# ESP32-S31 register map
Vendor: ESPRESSIF SYSTEMS (SHANGHAI) CO., LTD.; Series: ESP32 S-Series; File version: 1
CPU: RV32IMAFC r0p0, little endian, no MPU, FPU, 0 interrupt priority bits
Address unit: 32 bits
Registers are 32-bit, read-write, reset 0x0 unless marked. A register's access mark holds for its fields unless they carry their own. Offsets are from the block's base; [hi:lo] are bit positions; {n}, {i} and the like mark numbered series; 'fields as' and 'values as' point back to an identical list.

## IOMUX_MSPI_PIN — IOMUX_MSPI_PIN Peripheral
Base 0x20584000
0x00 CLK_EN0 reset 0x1 — apb registers auto clock gating reg
  [0] REG_CLK_EN — 1: auto clock gating on 0: auto clock gating off
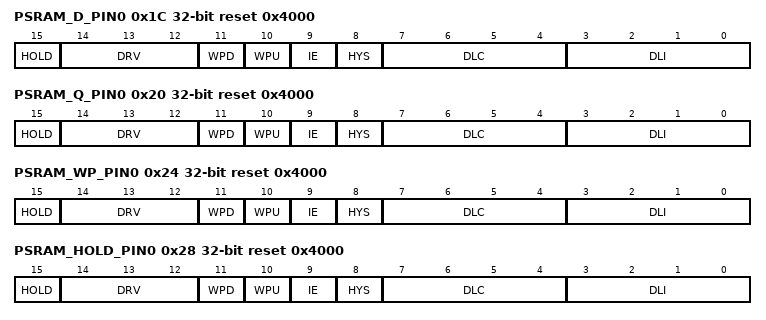
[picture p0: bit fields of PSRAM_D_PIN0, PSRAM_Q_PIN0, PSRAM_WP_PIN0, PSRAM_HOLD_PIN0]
0x1C PSRAM_D_PIN0 reset 0x4000 — IOMUX_MSPI_PIN_PSRAM_D_PIN0_REG
  [15] HOLD — psram d hold
  [14:12] DRV — psram d drv
  [11] WPD — psram d wpd
  [10] WPU — psram d wpu
  [9] IE — Reserved
  [8] HYS — psram d sl
  [7:4] DLC — psram d dlc
  [3:0] DLI — psram d dli
0x20 PSRAM_Q_PIN0 reset 0x4000 — IOMUX_MSPI_PIN_PSRAM_D_PIN0_REG
  fields as PSRAM_D_PIN0
0x24 PSRAM_WP_PIN0 reset 0x4000 — IOMUX_MSPI_PIN_PSRAM_D_PIN0_REG
  fields as PSRAM_D_PIN0
0x28 PSRAM_HOLD_PIN0 reset 0x4000 — IOMUX_MSPI_PIN_PSRAM_D_PIN0_REG
  fields as PSRAM_D_PIN0
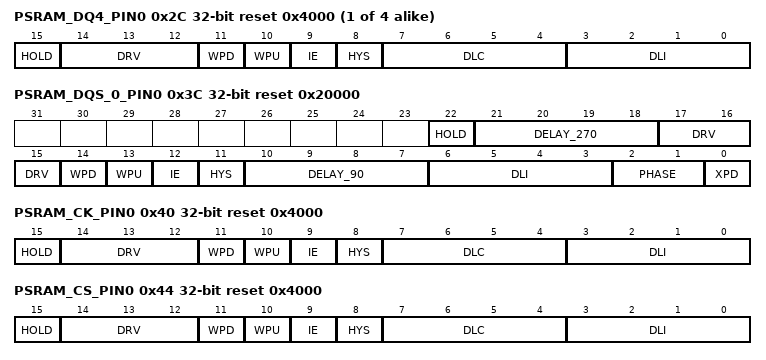
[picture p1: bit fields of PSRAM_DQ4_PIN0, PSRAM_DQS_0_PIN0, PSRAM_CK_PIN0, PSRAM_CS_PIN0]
{0x1C+4i} PSRAM_DQ{i}_PIN0 reset 0x4000 (i=4..7) — IOMUX_MSPI_PIN_PSRAM_D_PIN0_REG
  fields as PSRAM_D_PIN0
0x3C PSRAM_DQS_0_PIN0 reset 0x20000 — IOMUX_MSPI_PIN_PSRAM_D_PIN0_REG
  [22] HOLD — psram dqs hold
  [21:18] DELAY_270 — psram dqs0 delay 270
  [17:15] DRV — psram dqs0 drv
  [14] WPD — psram dqs0 wpd
  [13] WPU — psram dqs0 wpu
  [12] IE — Reserved
  [11] HYS — psram dqs0 sl
  [10:7] DELAY_90 — psram dqs0 delay 90
  [6:3] DLI — psram dqs0 dli
  [2:1] PHASE — psram dqs0 phase
  [0] XPD — psram xpd dqs0
0x40 PSRAM_CK_PIN0 reset 0x4000 — IOMUX_MSPI_PIN_PSRAM_D_PIN0_REG
  fields as PSRAM_D_PIN0
0x44 PSRAM_CS_PIN0 reset 0x4000 — IOMUX_MSPI_PIN_PSRAM_D_PIN0_REG
  fields as PSRAM_D_PIN0

## INTERRUPT_CORE0 — Interrupt Controller for Core 0
Base 0x20585000
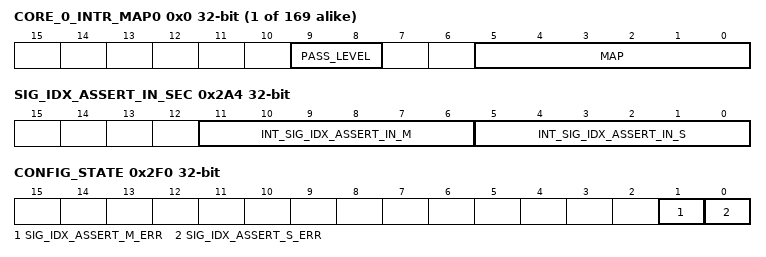
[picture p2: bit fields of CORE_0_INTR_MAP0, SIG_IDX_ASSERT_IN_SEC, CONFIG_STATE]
{0x0+4i} CORE_0_INTR_MAP{i} (i=0..168) — Interrupt-matrix destination and privilege routing for source {i}
  [9:8] PASS_LEVEL, [5:0] MAP
0x2A4 SIG_IDX_ASSERT_IN_SEC
  [11:6] INT_SIG_IDX_ASSERT_IN_M, [5:0] INT_SIG_IDX_ASSERT_IN_S
{0x2A8+4i} CORE_0_INTR_STATUS{i} (i=0..5) ro
  [31:0] INT_STATUS_0
{0x2C0+4i} SRC_PASS_IN_S_STATUS{i} (i=0..5) ro
  [31:0] INT_SRC_PASS_IN_S_STATUS_0
{0x2D8+4i} SRC_PASS_IN_M_STATUS{i} (i=0..5) ro
  [31:0] INT_SRC_PASS_IN_M_STATUS_0
0x2F0 CONFIG_STATE ro
  [1] SIG_IDX_ASSERT_M_ERR, [0] SIG_IDX_ASSERT_S_ERR
0x2F4 S_STATUS ro
  [31:0] INT_S_STATUS
0x2F8 M_STATUS ro
  [31:0] INT_M_STATUS
0x2FC CLOCK_GATE
  [0] REG_CLK_EN
0x7FC INTERRUPT_DATE reset 0x2509110
  [27:0] INTERRUPT_DATE

## INTERRUPT_CORE1 — Interrupt Controller for Core 1
Base 0x20585800
Registers as INTERRUPT_CORE0, without CORE_0_INTR_MAP*, CORE_0_INTR_STATUS*; these are added or differ:
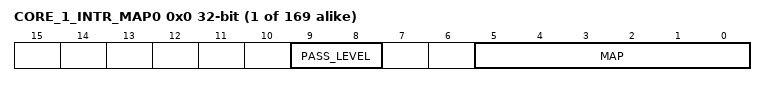
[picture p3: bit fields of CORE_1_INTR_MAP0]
{0x0+4i} CORE_1_INTR_MAP{i} (i=0..168) — Interrupt-matrix destination and privilege routing for source {i}
  [9:8] PASS_LEVEL, [5:0] MAP
{0x2A8+4i} CORE_1_INTR_STATUS{i} (i=0..5) ro
  [31:0] INT_STATUS_0

## IO_MUX — Input/Output Multiplexer
Base 0x20582000
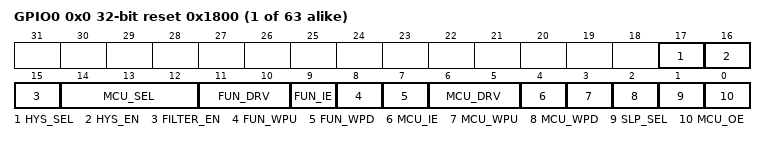
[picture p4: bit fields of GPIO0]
{0x0+4i} GPIO{i} (i=0..62) reset 0x1800 — IO MUX configuration register for GPIO{i}
  [17] HYS_SEL — Configures to choose the signal for enabling the hysteresis function for GPIO%s. \\ 0: Choose the output enable signal of eFuse\\ 1: Choose the output enable signal of IO_MUX_GPIO%s_HYS_EN\\
  [16] HYS_EN — Configures whether or not to enable the hysteresis function of the pin when IO_MUX_GPIO%s_HYS_SEL is set to 1.\\ 0: Disable\\ 1: Enable\\
  [15] FILTER_EN — Configures whether or not to enable filter for pin input signals.\\ 0: Disable\\ 1: Enable\\
  [14:12] MCU_SEL — Configures to select IO MUX function for this signal. \\ 0: Select Function 0\\ 1: Select Function 1\\ ......\\
  [11:10] FUN_DRV — Configures the drive strength of GPIO%s. \\ 0: ~5 mA\\ 1: ~10 mA\\ 2: ~20 mA\\ 3: ~40 mA\\
  [9] FUN_IE — Configures whether or not to enable input of GPIO%s.\\ 0: Disable\\ 1: Enable\\
  [8] FUN_WPU — Configures whether or not enable pull-up resistor of GPIO%s.\\ 0: Disable\\ 1: Enable\\
  [7] FUN_WPD — Configures whether or not to enable pull-down resistor of GPIO%s.\\ 0: Disable\\ 1: Enable\\
  [6:5] MCU_DRV — Configures the drive strength of GPIO%s during sleep mode. \\ 0: ~5 mA\\ 1: ~10 mA\\ 2: ~20 mA\\ 3: ~40 mA\\
  [4] MCU_IE — Configures whether or not to enable the input of GPIO%s during sleep mode.\\ 0: Disable\\ 1: Enable\\
  [3] MCU_WPU — Configures whether or not to enable pull-up resistor of GPIO%s during sleep mode. \\ 0: Disable\\ 1: Enable\\
  [2] MCU_WPD — Configure whether or not to enable pull-down resistor of GPIO%s in sleep mode.\\ 0: Disable\\ 1: Enable\\
  [1] SLP_SEL — Configures whether or not to enter sleep mode for GPIO%s.\\ 0: Not enter\\ 1: Enter\\
  [0] MCU_OE — Configures whether or not to enable the output of GPIO%s in sleep mode. 0: Disable\\ 1: Enable\\
0x1FC DATE reset 0x2502070 — Version control register
  [27:0] REG_DATE
